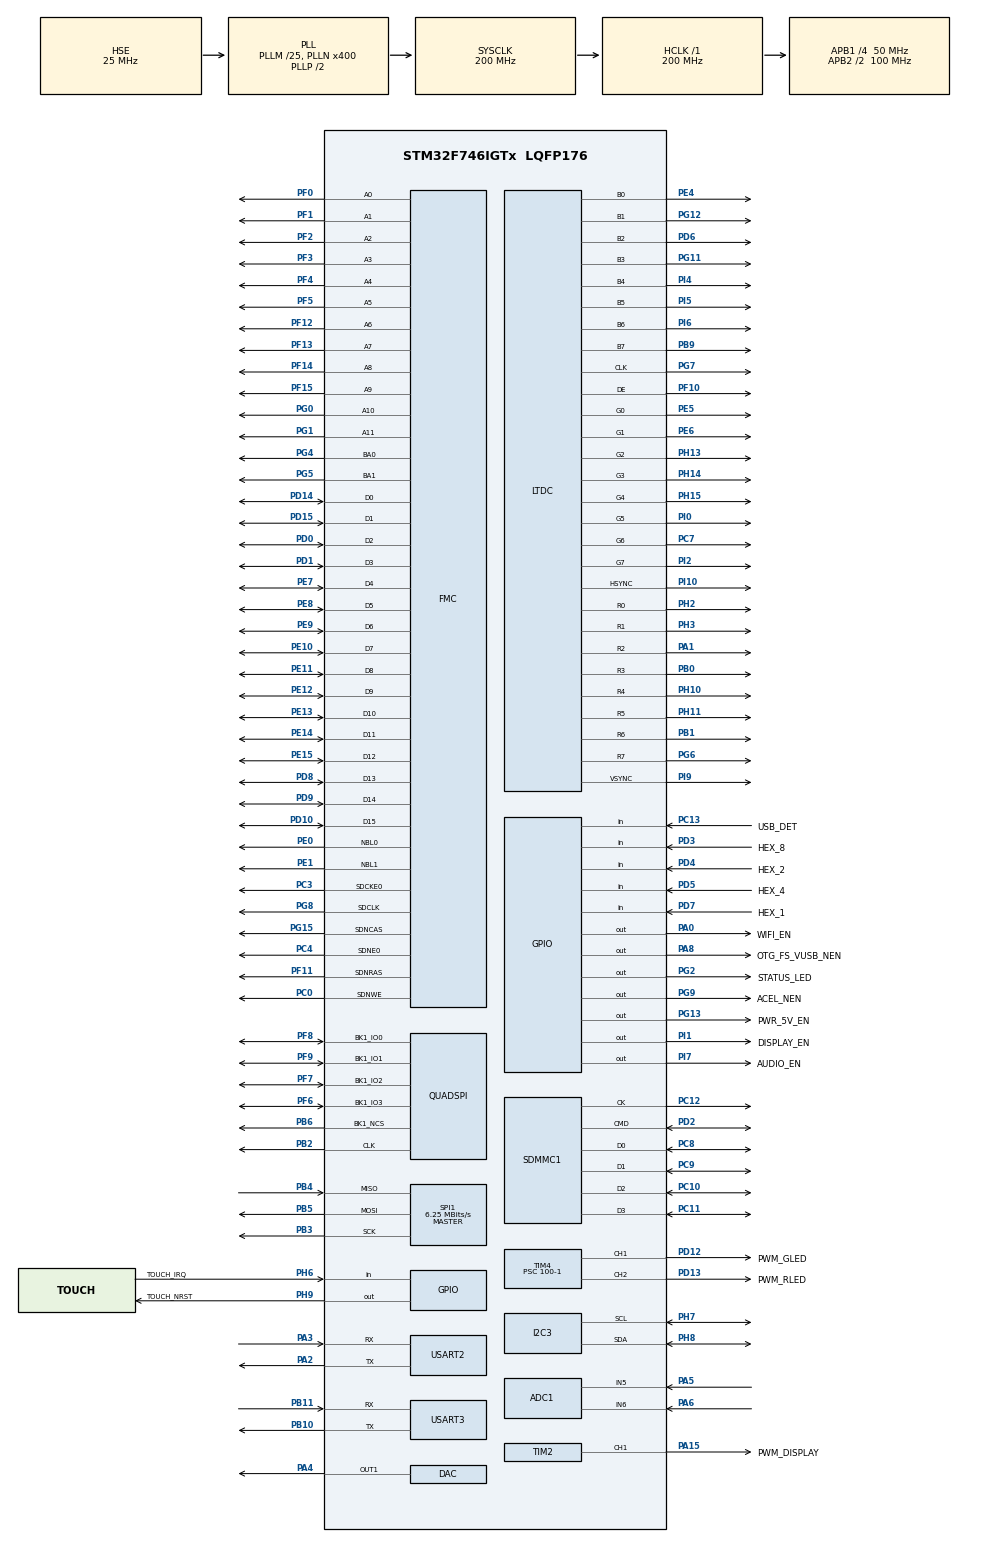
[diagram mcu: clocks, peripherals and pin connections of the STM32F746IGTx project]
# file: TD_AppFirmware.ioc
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FREERTOS.Queues01=AudioQueue,5,Type_AudioMsg,0,Dynamic,NULL,NULL
PD12.GPIO_Label=PWM_GLED
FATFS._USE_LFN=2
FMC.SDClockPeriod1=FMC_SDRAM_CLOCK_PERIOD_2
SH.FMC_A0.0=FMC_A0,12b-sda1
FATFS0.BSP.api=Unknown
VP_ADC1_TempSens_Input.Mode=IN-TempSens
NVIC.TIM6_DAC_IRQn=true\:0\:0\:false\:false\:true\:false\:false\:true
PG8.Signal=FMC_SDCLK
PG0.Signal=FMC_A10
SH.FMC_D5_DA5.0=FMC_D5,sd-16b-d1
VP_TIM1_VS_no_output1.Mode=Output Compare1 No Output
SH.FMC_D9_DA9.0=FMC_D9,sd-16b-d1
PF7.Signal=QUADSPI_BK1_IO2
NVIC.DMA2D_IRQn=true\:5\:0\:false\:false\:true\:true\:true\:true
RCC.PLL48CLockSelection=RCC_CLK48SOURCE_PLLSAIP
SH.FMC_SDNWE.0=FMC_SDNWE,12b-sda1
PH9.Signal=GPIO_Output
SPI1.Direction=SPI_DIRECTION_2LINES
SH.FMC_D11_DA11.0=FMC_D11,sd-16b-d1
Dma.SDMMC1_TX.2.Direction=DMA_MEMORY_TO_PERIPH
RCC.APB2TimFreq_Value=200000000
PB6.Signal=QUADSPI_BK1_NCS
Dma.ADC1.0.Direction=DMA_PERIPH_TO_MEMORY
PC7.Signal=LTDC_G6
SPI1.CalculateBaudRate=6.25 MBits/s
PD0.Signal=FMC_D2_DA2
PD8.Signal=FMC_D13_DA13
PE1.Signal=FMC_NBL1
QUADSPI.FlashSize=24
Dma.ADC1.0.MemDataAlignment=DMA_MDATAALIGN_HALFWORD
FATFS0.BSP.ip=GPIO
PB3.Mode=Full_Duplex_Master
ADC1.ScanConvMode=ADC_SCAN_ENABLE
FMC.SelfRefreshTime1=4
LTDC.PixelFormat_L0=LTDC_PIXEL_FORMAT_RGB888
PE9.Signal=FMC_D6_DA6
SH.FMC_A2.0=FMC_A2,12b-sda1
Dma.SDMMC1_TX.2.FIFOMode=DMA_FIFOMODE_ENABLE
SPI1.DataSize=SPI_DATASIZE_8BIT
PC9.Mode=SD_4_bits_Wide_bus
PA8.Signal=GPIO_Output
SH.FMC_D1_DA1.0=FMC_D1,sd-16b-d1
LTDC.HSync=41
PB9.Signal=LTDC_B7
Mcu.Package=LQFP176
TIM2.Prescaler=100-1
PB1.Signal=LTDC_R6
NVIC.TimeBase=TIM6_DAC_IRQn
PD12.Signal=S_TIM4_CH1
PH11.Mode=RGB888
NVIC.TimeBaseIP=TIM6
FMC.WriteRecoveryTime1=3
PC11.Mode=SD_4_bits_Wide_bus
RCC.APB2CLKDivider=RCC_HCLK_DIV2
SH.S_TIM4_CH1.0=TIM4_CH1,PWM Generation1 CH1
LTDC.VSync=10
RCC.APB1TimFreq_Value=100000000
PF10.Mode=RGB888
FMC.RowCycleDelay1=7
Dma.SDMMC1_TX.2.Instance=DMA2_Stream6
PH8.Mode=I2C
ADC1.EOCSelection=ADC_EOC_SEQ_CONV
PD15.Signal=FMC_D1_DA1
PG12.Signal=LTDC_B1
FATFS0.BSP.STBoard=false
SH.FMC_A4.0=FMC_A4,12b-sda1
FREERTOS.Tasks01=DefaultTouchGFx,24,8192,defaultTouchGFxTask,Default,NULL,Dynamic,NULL,NULL;GeneralHardware,8,512,generalHardwareTask,Default,NULL,Dynamic,NULL,NULL;AnalogDigital,8,128,analogDigitalTask,Default,NULL,Dynamic,NULL,NULL;PWM_Acceleromet,8,1024,PWM_AccelerometerTask,Default,NULL,Dynamic,NULL,NULL;WIFI_AP,8,256,WIFI_AP_Task,Default,NULL,Dynamic,NULL,NULL;AudioPlay,8,4096,audioPlayTask,Default,NULL,Dynamic,NULL,NULL
PH13.Signal=LTDC_G2
Dma.SDMMC1_RX.1.MemInc=DMA_MINC_ENABLE
TIM3.AutoReloadPreload=TIM_AUTORELOAD_PRELOAD_DISABLE
SH.ADCx_IN6.0=ADC1_IN6,IN6
PG5.Signal=FMC_A15_BA1
PC13.Signal=GPIO_Input
SH.FMC_D10_DA10.0=FMC_D10,sd-16b-d1
FATFS0.BSP.mode=Input
PD3.Signal=GPIO_Input
PI10.Mode=RGB888
PD6.Mode=RGB888
RCC.PLLSAIRDiv=RCC_PLLSAIDIVR_8
LTDC.ImageWidth_L0=480
PD10.Signal=FMC_D15_DA15
PA3.Mode=Asynchronous
TIM1.AutoReloadPreload=TIM_AUTORELOAD_PRELOAD_ENABLE
PA8.GPIO_Label=OTG_FS_VUSB_NEN
Dma.ADC1.0.Priority=DMA_PRIORITY_LOW
PI6.Mode=RGB888
NVIC.DMA2_Stream6_IRQn=true\:15\:0\:true\:false\:true\:true\:false\:true
PA5.Signal=ADCx_IN5
PC12.Mode=SD_4_bits_Wide_bus
NVIC.TIM3_IRQn=true\:5\:0\:false\:false\:true\:true\:true\:true
PI7.Signal=GPIO_Output
FMC.ReadBurst1=FMC_SDRAM_RBURST_ENABLE
TIM1.TIM_MasterOutputTrigger=TIM_TRGO_UPDATE
SH.FMC_A6.0=FMC_A6,12b-sda1
PE14.Signal=FMC_D11_DA11
PE6.Mode=RGB888
SPI1.Mode=SPI_MODE_MASTER
PI2.Signal=LTDC_G7
QUADSPI.FifoThreshold=4
PF13.Signal=FMC_A7
TIM2.Period=100-1
Dma.SDMMC1_TX.2.MemInc=DMA_MINC_ENABLE
ADC1.ExternalTrigConv=ADC_EXTERNALTRIGCONV_T1_TRGO
PC8.Mode=SD_4_bits_Wide_bus
ADC1.master=1
Dma.SDMMC1_RX.1.MemBurst=DMA_MBURST_INC4
ProjectManager.HeapSize=0xA00
PB1.Mode=RGB888
PH6.Signal=GPIO_Input
NVIC.PriorityGroup=NVIC_PRIORITYGROUP_4
Dma.SDMMC1_RX.1.Priority=DMA_PRIORITY_LOW
PC15/OSC32_OUT.Signal=RCC_OSC32_OUT
PF4.Signal=FMC_A4
PD2.Signal=SDMMC1_CMD
FATFS0.BSP.name=Detect_SDIO
PI1.GPIO_Label=DISPLAY_EN
Mcu.Family=STM32F7
SH.FMC_A8.0=FMC_A8,12b-sda1
FREERTOS.BinarySemaphores01=BinarySemAnalogDigital,Dynamic,NULL;BinarySemPWM_Accelerometer,Dynamic,NULL;BinarySemWIFI_AP,Dynamic,NULL
PH14.Signal=LTDC_G3
PH10.Signal=LTDC_R4
SH.FMC_D14_DA14.0=FMC_D14,sd-16b-d1
PG2.Signal=GPIO_Output
PC14/OSC32_IN.Mode=LSE-External-Oscillator
SH.FMC_A14_BA0.0=FMC_BA0,FourSdramBanks1
SH.FMC_A11.0=FMC_A11,12b-sda1
PI5.Mode=RGB888
PG11.Signal=LTDC_B3
PG15.Signal=FMC_SDNCAS
PD13.Signal=S_TIM4_CH2
PA15.GPIO_Label=PWM_DISPLAY
TIM1.Prescaler=1000-1
STMicroelectronics.X-CUBE-TOUCHGFX.4.16.0.tgfx_location=By Address
ADC1.Channel-3\#ChannelRegularConversion=ADC_CHANNEL_TEMPSENSOR
TIM3.Period=1000-1
Dma.SDMMC1_TX.2.FIFOThreshold=DMA_FIFO_THRESHOLD_FULL
PH10.Mode=RGB888
SH.FMC_NBL1.0=FMC_NBL1,Sd2ByteEnable1
LTDC.WindowX1_L0=480
PI9.Mode=RGB888
ADC1.Channel-0\#ChannelRegularConversion=ADC_CHANNEL_5
RCC.HSE_VALUE=25000000
STMicroelectronics.X-CUBE-TOUCHGFX.4.16.0.tgfx_display_interface=disp_ltdc
FMC.ExitSelfRefreshDelay1=7
PF9.Mode=Single Bank 1
PA14.Mode=Serial_Wire
TIM3.Prescaler=100-1
PF11.Signal=FMC_SDNRAS
PB5.Mode=Full_Duplex_Master
TIM2.Channel-PWM\ Generation1\ CH1=TIM_CHANNEL_1
QUADSPI.SampleShifting=QSPI_SAMPLE_SHIFTING_HALFCYCLE
PD13.GPIO_Label=PWM_RLED
PA6.Signal=ADCx_IN6
PD5.GPIO_Label=HEX_4
PA15.Signal=S_TIM2_CH1_ETR
PF8.Signal=QUADSPI_BK1_IO0
I2C3.Timing=0x00C0EAFF
Dma.Request2=SDMMC1_TX
Dma.Request1=SDMMC1_RX
PD3.GPIO_Label=HEX_8
PH2.Mode=RGB888
PE7.Signal=FMC_D4_DA4
Dma.SDMMC1_RX.1.PeriphInc=DMA_PINC_DISABLE
PD6.Signal=LTDC_B2
Dma.Request0=ADC1
VP_TIM3_VS_ClockSourceINT.Mode=Internal
PB4.Signal=SPI1_MISO
PG2.GPIO_Label=STATUS_LED
PA3.Signal=USART2_RX
QUADSPI.ChipSelectHighTime=QSPI_CS_HIGH_TIME_6_CYCLE
NVIC.LTDC_IRQn=true\:5\:0\:false\:false\:true\:true\:true\:true
LTDC.WindowY1_L0=272
PG7.Signal=LTDC_CLK
PC11.Signal=SDMMC1_D3
PC8.Signal=SDMMC1_D0
PC10.Mode=SD_4_bits_Wide_bus
PD9.Signal=FMC_D14_DA14
FATFS0.BSP.instance=PC13
PA13.Signal=SYS_JTMS-SWDIO
Dma.ADC1.0.PeriphDataAlignment=DMA_PDATAALIGN_HALFWORD
PF6.Signal=QUADSPI_BK1_IO3
SH.FMC_D13_DA13.0=FMC_D13,sd-16b-d1
PH8.Signal=I2C3_SDA
Dma.SDMMC1_RX.1.MemDataAlignment=DMA_MDATAALIGN_WORD
PB9.Mode=RGB888
RCC.USBFreq_Value=48000000
PH13.Mode=RGB888
TIM4.Prescaler=100-1
PA1.Signal=LTDC_R2
PD2.Mode=SD_4_bits_Wide_bus
board=custom
PG12.Mode=RGB888
RCC.VCOOutputFreq_Value=400000000
PI9.Signal=LTDC_VSYNC
PI4.Signal=LTDC_B4
PE5.Mode=RGB888
SH.FMC_D12_DA12.0=FMC_D12,sd-16b-d1
PF1.Signal=FMC_A1
ADC1.NbrOfConversion=3
PE0.Signal=FMC_NBL0
PE12.Signal=FMC_D9_DA9
RCC.SYSCLKFreq_VALUE=200000000
ADC1.Rank-3\#ChannelRegularConversion=3
ADC1.SamplingTime-3\#ChannelRegularConversion=ADC_SAMPLETIME_480CYCLES
PB2.Mode=Single Bank 1
Dma.ADC1.0.MemInc=DMA_MINC_ENABLE
RCC.HSI_VALUE=16000000
RCC.PLLQ=8
PH3.Signal=LTDC_R1
RCC.PLLM=25
RCC.PLLN=400
PA2.Mode=Asynchronous
Dma.SDMMC1_RX.1.FIFOThreshold=DMA_FIFO_THRESHOLD_FULL
CORTEX_M7.CPU_DCache=Enabled
PH9.PinState=GPIO_PIN_SET
VP_CRC_VS_CRC.Mode=CRC_Activate
LTDC.ImageHeight_L0=272
SH.FMC_D7_DA7.0=FMC_D7,sd-16b-d1
VP_SYS_VS_tim6.Mode=TIM6
FMC.RCDDelay1=2
Dma.SDMMC1_RX.1.PeriphDataAlignment=DMA_PDATAALIGN_WORD
QUADSPI.ClockPrescaler=1
SPI1.VirtualType=VM_MASTER
PB10.Mode=Asynchronous
VP_FATFS_VS_SDIO.Mode=SDIO
PG4.Signal=FMC_A14_BA0
PC12.Signal=SDMMC1_CK
PH6.GPIO_Label=TOUCH_IRQ
FMC.LoadToActiveDelay1=2
VP_STMicroelectronics.X-CUBE-TOUCHGFX_VS_GraphicsJjApplication_4.16.0.Mode=GraphicsJjApplication
PG6.Mode=RGB888
PG13.Signal=GPIO_Output
RCC.SYSCLKSource=RCC_SYSCLKSOURCE_PLLCLK
SH.FMC_A15_BA1.0=FMC_BA1,FourSdramBanks1
USART3.VirtualMode-Asynchronous=VM_ASYNC
NVIC.SDMMC1_IRQn=true\:14\:0\:true\:false\:true\:true\:true\:true
STMicroelectronics.X-CUBE-TOUCHGFX.4.16.0.tgfx_hardware_accelerator=dma_2d
Dma.SDMMC1_TX.2.PeriphInc=DMA_PINC_DISABLE
PD4.Signal=GPIO_Input
TIM4.Pulse-PWM\ Generation1\ CH1=50-1
PH1/OSC_OUT.Signal=RCC_OSC_OUT
PB6.Mode=Single Bank 1
PC3.Signal=FMC_SDCKE0
PE5.Signal=LTDC_G0
PB2.Signal=QUADSPI_CLK
FATFS0.BSP.i2caddr=0
PI6.Signal=LTDC_B6
Dma.ADC1.0.PeriphInc=DMA_PINC_DISABLE
SH.S_TIM4_CH2.0=TIM4_CH2,PWM Generation2 CH2
PF8.Mode=Single Bank 1
TIM4.Period=100-1
PF3.Signal=FMC_A3
PE10.Signal=FMC_D7_DA7
ADC1.SamplingTime-0\#ChannelRegularConversion=ADC_SAMPLETIME_28CYCLES
RCC.SDMMCClockSelection=RCC_SDMMC1CLKSOURCE_CLK48
FATFS0.BSP.solution=PC13
SH.FMC_A1.0=FMC_A1,12b-sda1
PH2.Signal=LTDC_R0
SH.FMC_SDCLK.0=FMC_SDCLK,12b-sda1
PF14.Signal=FMC_A8
VP_DMA2D_VS_DMA2D.Mode=DMA2D_Activate
Dma.ADC1.0.FIFOMode=DMA_FIFOMODE_DISABLE
TIM1.Period=100-1
SH.FMC_D3_DA3.0=FMC_D3,sd-16b-d1
TIM4.Pulse-PWM\ Generation2\ CH2=50-1
PC4.Mode=SdramChipSelect1_1
PH15.Signal=LTDC_G4
Dma.ADC1.0.Instance=DMA2_Stream0
ADC1.Rank-0\#ChannelRegularConversion=1
PI4.Mode=RGB888
PG9.Signal=GPIO_Output
TIM1.Channel-Output\ Compare1\ No\ Output=TIM_CHANNEL_1
PD7.Signal=GPIO_Input
PD1.Signal=FMC_D3_DA3
STMicroelectronics.X-CUBE-TOUCHGFX.4.16.0.tgfx_buffering_strategy=Double
PC0.Signal=FMC_SDNWE
Dma.SDMMC1_TX.2.PeriphBurst=DMA_PBURST_INC4
RCC.APB1CLKDivider=RCC_HCLK_DIV4
Dma.SDMMC1_TX.2.MemBurst=DMA_MBURST_INC4
PG13.GPIO_Label=PWR_5V_EN
PI2.Mode=RGB888
SH.FMC_A3.0=FMC_A3,12b-sda1
FMC.CASLatency1=FMC_SDRAM_CAS_LATENCY_3
PB11.Mode=Asynchronous
SH.FMC_D15_DA15.0=FMC_D15,sd-16b-d1
PB10.Signal=USART3_TX
FATFS.BSP.number=1
PH9.GPIO_Label=TOUCH_NRST
PH14.Mode=RGB888
Dma.SDMMC1_TX.2.Priority=DMA_PRIORITY_LOW
PA1.Mode=RGB888
PE15.Signal=FMC_D12_DA12
PE8.Signal=FMC_D5_DA5
PI1.Signal=GPIO_Output
PA0/WKUP.GPIO_Label=WIFI_EN
ADC1.DMAContinuousRequests=ENABLE
PA13.Mode=Serial_Wire
SH.FMC_SDNCAS.0=FMC_SDNCAS,12b-sda1
Dma.SDMMC1_TX.2.Mode=DMA_PFCTRL
PA4.Signal=COMP_DAC1_group
ADC1.SamplingTime-1\#ChannelRegularConversion=ADC_SAMPLETIME_15CYCLES
PB5.Signal=SPI1_MOSI
ADC1.Rank-1\#ChannelRegularConversion=2
SH.FMC_A5.0=FMC_A5,12b-sda1
PG11.Mode=RGB888
LTDC.Alpha_L0=255
Dma.SDMMC1_RX.1.PeriphBurst=DMA_PBURST_INC4
SH.S_TIM2_CH1_ETR.0=TIM2_CH1,PWM Generation1 CH1
PF6.Mode=Single Bank 1
NVIC.TIM1_UP_TIM10_IRQn=true\:5\:0\:false\:false\:true\:true\:true\:true
PF9.Signal=QUADSPI_BK1_IO1
STMicroelectronics.X-CUBE-TOUCHGFX.4.16.0.tgfx_vsync=vsync_ltdc
SH.ADCx_IN5.0=ADC1_IN5,IN5
VP_TIM4_VS_ClockSourceINT.Mode=Internal
PB0.Signal=LTDC_R3
Dma.SDMMC1_RX.1.Direction=DMA_PERIPH_TO_MEMORY
NVIC.USART3_IRQn=true\:5\:0\:false\:false\:true\:true\:true\:true
PC3.Mode=SdramChipSelect1_1
RCC.CortexFreq_Value=200000000
PG6.Signal=LTDC_R7
USART2.SwapParam=ADVFEATURE_SWAP_ENABLE
LTDC.HBP=13
PC10.Signal=SDMMC1_D2
SH.FMC_NBL0.0=FMC_NBL0,Sd2ByteEnable1
SH.FMC_D6_DA6.0=FMC_D6,sd-16b-d1
PA0/WKUP.Signal=GPIO_Output
PC13.GPIO_Label=USB_DET
PB11.Signal=USART3_RX
ProjectManager.StackSize=0xA00
VP_FREERTOS_VS_CMSIS_V2.Mode=CMSIS_V2
PH3.Mode=RGB888
Dma.SDMMC1_TX.2.MemDataAlignment=DMA_MDATAALIGN_WORD
SH.FMC_A7.0=FMC_A7,12b-sda1
Dma.SDMMC1_RX.1.Mode=DMA_PFCTRL
PH0/OSC_IN.Mode=HSE-External-Oscillator
RCC.HCLKFreq_Value=200000000
STMicroelectronics.X-CUBE-TOUCHGFX.4.16.0.tgfx_oswrapper=CMSIS V2
PF12.Signal=FMC_A6
NVIC.DMA2_Stream0_IRQn=true\:7\:0\:true\:false\:true\:true\:false\:true
SH.FMC_A10.0=FMC_A10,12b-sda1
RCC.AHBFreq_Value=200000000
SH.FMC_D8_DA8.0=FMC_D8,sd-16b-d1
USART2.VirtualMode-Asynchronous=VM_ASYNC
FMC.RPDelay1=2
SH.FMC_D2_DA2.0=FMC_D2,sd-16b-d1
PB4.Mode=Full_Duplex_Master
PE13.Signal=FMC_D10_DA10
PI5.Signal=LTDC_B5
PI0.Signal=LTDC_G5
LTDC.HFP=32
PE4.Mode=RGB888
SH.FMC_SDNRAS.0=FMC_SDNRAS,12b-sda1
DMA2D.ColorMode=DMA2D_OUTPUT_RGB888
LTDC.ActiveW=480
PE4.Signal=LTDC_B0
PH1/OSC_OUT.Mode=HSE-External-Oscillator
FREERTOS.configTOTAL_HEAP_SIZE=60000
STMicroelectronics.X-CUBE-TOUCHGFX.4.16.0.tgfx_address1=0xC0000000
STMicroelectronics.X-CUBE-TOUCHGFX.4.16.0.tgfx_address2=0xC005FA00
PH7.Mode=I2C
PD7.GPIO_Label=HEX_1
SH.FMC_D0_DA0.0=FMC_D0,sd-16b-d1
PC14/OSC32_IN.Signal=RCC_OSC32_IN
SH.FMC_A9.0=FMC_A9,12b-sda1
SH.FMC_D4_DA4.0=FMC_D4,sd-16b-d1
RCC.PLLSAIN=384
PF5.Signal=FMC_A5
RCC.PLLSAIP=RCC_PLLSAIP_DIV8
RCC.PLLSAIR=5
PH7.Signal=I2C3_SCL
PF0.Signal=FMC_A0
SPI1.BaudRatePrescaler=SPI_BAUDRATEPRESCALER_16
RCC.PLLSourceVirtual=RCC_PLLSOURCE_HSE
TIM4.Channel-PWM\ Generation1\ CH1=TIM_CHANNEL_1
SH.COMP_DAC1_group.0=DAC_OUT1,DAC_OUT1
LTDC.FBStartAdress_L0=0xC0000000
CORTEX_M7.CPU_ICache=Enabled
PH11.Signal=LTDC_R5
Dma.SDMMC1_RX.1.Instance=DMA2_Stream3
PG1.Signal=FMC_A11
PC4.Signal=FMC_SDNE0
PI10.Signal=LTDC_HSYNC
PD5.Signal=GPIO_Input
NVIC.USART2_IRQn=true\:5\:0\:false\:false\:true\:true\:true\:true
TIM2.Pulse-PWM\ Generation1\ CH1=50-1
PF7.Mode=Single Bank 1
ProjectManager.TargetToolchain=STM32CubeIDE
Dma.ADC1.0.Mode=DMA_CIRCULAR
LTDC.ActiveH=272
PI0.Mode=RGB888
ADC1.Channel-1\#ChannelRegularConversion=ADC_CHANNEL_6
PF2.Signal=FMC_A2
STMicroelectronics.X-CUBE-TOUCHGFX.4.16.0.ApplicationCcGraphicsJjApplication=TouchGFXOoGenerator
NVIC.DMA2_Stream3_IRQn=true\:15\:0\:true\:false\:true\:true\:false\:true
PE11.Signal=FMC_D8_DA8
PG7.Mode=RGB888
PG9.GPIO_Label=ACEL_NEN
PB0.Mode=RGB888
PH0/OSC_IN.Signal=RCC_OSC_IN
TIM4.Channel-PWM\ Generation2\ CH2=TIM_CHANNEL_2
RCC.APB2Freq_Value=100000000
LTDC.Layers=0
VP_TIM2_VS_ClockSourceINT.Mode=Internal
PD4.GPIO_Label=HEX_2
PF10.Signal=LTDC_DE
PI7.GPIO_Label=AUDIO_EN
PF15.Signal=FMC_A9
PE6.Signal=LTDC_G1
Dma.SDMMC1_RX.1.FIFOMode=DMA_FIFOMODE_ENABLE
Mcu.Name=STM32F746IGTx
PA2.Signal=USART2_TX
Dma.SDMMC1_TX.2.PeriphDataAlignment=DMA_PDATAALIGN_WORD
PH15.Mode=RGB888
PD14.Signal=FMC_D0_DA0
PB3.Signal=SPI1_SCK
PC15/OSC32_OUT.Mode=LSE-External-Oscillator
PA14.Signal=SYS_JTCK-SWCLK
ADC1.NbrOfConversionFlag=1
PC9.Signal=SDMMC1_D1
PC7.Mode=RGB888
RCC.APB1Freq_Value=50000000

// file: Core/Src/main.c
/* USER CODE BEGIN Header */
/**
  ******************************************************************************
  * @file           : main.c
  * @brief          : Main program body
  ******************************************************************************
  * @attention
  *
  * <h2><center>&copy; Copyright (c) 2021 STMicroelectronics.
  * All rights reserved.</center></h2>
  *
  * This software component is licensed by ST under BSD 3-Clause license,
  * the "License"; You may not use this file except in compliance with the
  * License. You may obtain a copy of the License at:
  *                        opensource.org/licenses/BSD-3-Clause
  *
  ******************************************************************************
  */
/* USER CODE END Header */
#include "main.h"
#include "cmsis_os.h"
#include "adc.h"
#include "crc.h"
#include "dac.h"
#include "dma.h"
#include "dma2d.h"
#include "fatfs.h"
#include "i2c.h"
#include "ltdc.h"
#include "quadspi.h"
#include "sdmmc.h"
#include "spi.h"
#include "tim.h"
#include "usart.h"
#include "gpio.h"
#include "fmc.h"
#include "app_touchgfx.h"

/* USER CODE BEGIN Includes */
#include "MainSupport.h"
#include "AudioPlayTaskSupport.h"
/* USER CODE END Includes */

void SystemClock_Config(void);
void MX_FREERTOS_Init(void);

int main(void)
{

  /* Enable I-Cache---------------------------------------------------------*/
  SCB_EnableICache();

  /* Enable D-Cache---------------------------------------------------------*/
  SCB_EnableDCache();

  /* MCU Configuration--------------------------------------------------------*/

  /* Reset of all peripherals, Initializes the Flash interface and the Systick. */
  HAL_Init();

  /* Configure the system clock */
  SystemClock_Config();

  /* Initialize all configured peripherals */
  MX_GPIO_Init();
  MX_DMA_Init();
  MX_DMA2D_Init();
  MX_FMC_Init();
  MX_LTDC_Init();
  MX_QUADSPI_Init();
  MX_CRC_Init();
  MX_I2C3_Init();
  MX_TIM2_Init();
  MX_USART3_UART_Init();
  MX_ADC1_Init();
  MX_TIM1_Init();
  MX_SPI1_Init();
  MX_TIM4_Init();
  MX_USART2_UART_Init();
  MX_DAC_Init();
  MX_SDMMC1_SD_Init();
  MX_TIM3_Init();
  MX_FATFS_Init();
  MX_TouchGFX_Init();

  /* Init scheduler */
  osKernelInitialize();  /* Call init function for freertos objects (in freertos.c) */
  MX_FREERTOS_Init();
  /* Start scheduler */
  osKernelStart();

  /* We should never get here as control is now taken by the scheduler */
  /* Infinite loop */
  while (1)
  {

  }
}

void SystemClock_Config(void)
{
  RCC_OscInitTypeDef RCC_OscInitStruct = {0};
  RCC_ClkInitTypeDef RCC_ClkInitStruct = {0};
  RCC_PeriphCLKInitTypeDef PeriphClkInitStruct = {0};

  /** Configure LSE Drive Capability
  */
  HAL_PWR_EnableBkUpAccess();
  /** Configure the main internal regulator output voltage
  */
  __HAL_RCC_PWR_CLK_ENABLE();
  __HAL_PWR_VOLTAGESCALING_CONFIG(PWR_REGULATOR_VOLTAGE_SCALE1);
  /** Initializes the RCC Oscillators according to the specified parameters
  * in the RCC_OscInitTypeDef structure.
  */
  RCC_OscInitStruct.OscillatorType = RCC_OSCILLATORTYPE_HSE;
  RCC_OscInitStruct.HSEState = RCC_HSE_ON;
  RCC_OscInitStruct.PLL.PLLState = RCC_PLL_ON;
  RCC_OscInitStruct.PLL.PLLSource = RCC_PLLSOURCE_HSE;
  RCC_OscInitStruct.PLL.PLLM = 25;
  RCC_OscInitStruct.PLL.PLLN = 400;
  RCC_OscInitStruct.PLL.PLLP = RCC_PLLP_DIV2;
  RCC_OscInitStruct.PLL.PLLQ = 8;
  if (HAL_RCC_OscConfig(&RCC_OscInitStruct) != HAL_OK)
  {
    Error_Handler();
  }
  /** Activate the Over-Drive mode
  */
  if (HAL_PWREx_EnableOverDrive() != HAL_OK)
  {
    Error_Handler();
  }
  /** Initializes the CPU, AHB and APB buses clocks
  */
  RCC_ClkInitStruct.ClockType = RCC_CLOCKTYPE_HCLK|RCC_CLOCKTYPE_SYSCLK
                              |RCC_CLOCKTYPE_PCLK1|RCC_CLOCKTYPE_PCLK2;
  RCC_ClkInitStruct.SYSCLKSource = RCC_SYSCLKSOURCE_PLLCLK;
  RCC_ClkInitStruct.AHBCLKDivider = RCC_SYSCLK_DIV1;
  RCC_ClkInitStruct.APB1CLKDivider = RCC_HCLK_DIV4;
  RCC_ClkInitStruct.APB2CLKDivider = RCC_HCLK_DIV2;

  if (HAL_RCC_ClockConfig(&RCC_ClkInitStruct, FLASH_LATENCY_6) != HAL_OK)
  {
    Error_Handler();
  }
  PeriphClkInitStruct.PeriphClockSelection = RCC_PERIPHCLK_LTDC|RCC_PERIPHCLK_USART2
                              |RCC_PERIPHCLK_USART3|RCC_PERIPHCLK_I2C3
                              |RCC_PERIPHCLK_SDMMC1|RCC_PERIPHCLK_CLK48;
  PeriphClkInitStruct.PLLSAI.PLLSAIN = 384;
  PeriphClkInitStruct.PLLSAI.PLLSAIR = 5;
  PeriphClkInitStruct.PLLSAI.PLLSAIQ = 2;
  PeriphClkInitStruct.PLLSAI.PLLSAIP = RCC_PLLSAIP_DIV8;
  PeriphClkInitStruct.PLLSAIDivQ = 1;
  PeriphClkInitStruct.PLLSAIDivR = RCC_PLLSAIDIVR_8;
  PeriphClkInitStruct.Usart2ClockSelection = RCC_USART2CLKSOURCE_PCLK1;
  PeriphClkInitStruct.Usart3ClockSelection = RCC_USART3CLKSOURCE_PCLK1;
  PeriphClkInitStruct.I2c3ClockSelection = RCC_I2C3CLKSOURCE_PCLK1;
  PeriphClkInitStruct.Clk48ClockSelection = RCC_CLK48SOURCE_PLLSAIP;
  PeriphClkInitStruct.Sdmmc1ClockSelection = RCC_SDMMC1CLKSOURCE_CLK48;
  if (HAL_RCCEx_PeriphCLKConfig(&PeriphClkInitStruct) != HAL_OK)
  {
    Error_Handler();
  }
}

 /**
  * @brief  Period elapsed callback in non blocking mode
  * @note   This function is called  when TIM6 interrupt took place, inside
  * HAL_TIM_IRQHandler(). It makes a direct call to HAL_IncTick() to increment
  * a global variable "uwTick" used as application time base.
  * @param  htim : TIM handle
  * @retval None
  */
void HAL_TIM_PeriodElapsedCallback(TIM_HandleTypeDef *htim)
{
  if (htim->Instance == TIM6) {
    HAL_IncTick();
  }
  /* USER CODE BEGIN Callback 1 */
  if (htim->Instance == TIM3)
	  callbackHandlerTimer3();

  /* USER CODE END Callback 1 */
}

void Error_Handler(void)
{
  __disable_irq();
  while (1)
  {
  }
}

/************************ (C) COPYRIGHT STMicroelectronics *****END OF FILE****/

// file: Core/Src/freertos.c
/* USER CODE BEGIN Header */
/**
  ******************************************************************************
  * File Name          : freertos.c
  * Description        : Code for freertos applications
  ******************************************************************************
  * @attention
  *
  * <h2><center>&copy; Copyright (c) 2021 STMicroelectronics.
  * All rights reserved.</center></h2>
  *
  * This software component is licensed by ST under Ultimate Liberty license
  * SLA0044, the "License"; You may not use this file except in compliance with
  * the License. You may obtain a copy of the License at:
  *                             www.st.com/SLA0044
  *
  ******************************************************************************
  */
/* USER CODE END Header */

#include "FreeRTOS.h"
#include "task.h"
#include "main.h"
#include "cmsis_os.h"

/* USER CODE BEGIN Includes */
#include "MainSupport.h"
#include "TD_SDRAM.h"
#include "TD_SupportIO.h"
#include "app_touchgfx.h"
#include "AnalogDigitalTaskSupport.h"
#include "PWM_AccelerometerTaskSupport.h"
#include "AudioPlayTaskSupport.h"
/* USER CODE END Includes */

/* Definitions for DefaultTouchGFx */
osThreadId_t DefaultTouchGFxHandle;
const osThreadAttr_t DefaultTouchGFx_attributes = {
  .name = "DefaultTouchGFx",
  .priority = (osPriority_t) osPriorityNormal,
  .stack_size = 8192 * 4
};
/* Definitions for GeneralHardware */
osThreadId_t GeneralHardwareHandle;
const osThreadAttr_t GeneralHardware_attributes = {
  .name = "GeneralHardware",
  .priority = (osPriority_t) osPriorityLow,
  .stack_size = 512 * 4
};
/* Definitions for AnalogDigital */
osThreadId_t AnalogDigitalHandle;
const osThreadAttr_t AnalogDigital_attributes = {
  .name = "AnalogDigital",
  .priority = (osPriority_t) osPriorityLow,
  .stack_size = 128 * 4
};
/* Definitions for PWM_Acceleromet */
osThreadId_t PWM_AccelerometHandle;
const osThreadAttr_t PWM_Acceleromet_attributes = {
  .name = "PWM_Acceleromet",
  .priority = (osPriority_t) osPriorityLow,
  .stack_size = 1024 * 4
};
/* Definitions for WIFI_AP */
osThreadId_t WIFI_APHandle;
const osThreadAttr_t WIFI_AP_attributes = {
  .name = "WIFI_AP",
  .priority = (osPriority_t) osPriorityLow,
  .stack_size = 256 * 4
};
/* Definitions for AudioPlay */
osThreadId_t AudioPlayHandle;
const osThreadAttr_t AudioPlay_attributes = {
  .name = "AudioPlay",
  .priority = (osPriority_t) osPriorityLow,
  .stack_size = 4096 * 4
};
/* Definitions for AudioQueue */
osMessageQueueId_t AudioQueueHandle;
const osMessageQueueAttr_t AudioQueue_attributes = {
  .name = "AudioQueue"
};
/* Definitions for BinarySemAnalogDigital */
osSemaphoreId_t BinarySemAnalogDigitalHandle;
const osSemaphoreAttr_t BinarySemAnalogDigital_attributes = {
  .name = "BinarySemAnalogDigital"
};
/* Definitions for BinarySemPWM_Accelerometer */
osSemaphoreId_t BinarySemPWM_AccelerometerHandle;
const osSemaphoreAttr_t BinarySemPWM_Accelerometer_attributes = {
  .name = "BinarySemPWM_Accelerometer"
};
/* Definitions for BinarySemWIFI_AP */
osSemaphoreId_t BinarySemWIFI_APHandle;
const osSemaphoreAttr_t BinarySemWIFI_AP_attributes = {
  .name = "BinarySemWIFI_AP"
};

void defaultTouchGFxTask(void *argument);
void generalHardwareTask(void *argument);
void analogDigitalTask(void *argument);
void PWM_AccelerometerTask(void *argument);
void WIFI_AP_Task(void *argument);
void audioPlayTask(void *argument);

void MX_FREERTOS_Init(void); /* (MISRA C 2004 rule 8.1) */

void MX_FREERTOS_Init(void) {

  /* Create the semaphores(s) */
  /* creation of BinarySemAnalogDigital */
  BinarySemAnalogDigitalHandle = osSemaphoreNew(1, 1, &BinarySemAnalogDigital_attributes);

  /* creation of BinarySemPWM_Accelerometer */
  BinarySemPWM_AccelerometerHandle = osSemaphoreNew(1, 1, &BinarySemPWM_Accelerometer_attributes);

  /* creation of BinarySemWIFI_AP */
  BinarySemWIFI_APHandle = osSemaphoreNew(1, 1, &BinarySemWIFI_AP_attributes);

  /* Create the queue(s) */
  /* creation of AudioQueue */
  AudioQueueHandle = osMessageQueueNew (5, sizeof(Type_AudioMsg), &AudioQueue_attributes);

  /* Create the thread(s) */
  /* creation of DefaultTouchGFx */
  DefaultTouchGFxHandle = osThreadNew(defaultTouchGFxTask, NULL, &DefaultTouchGFx_attributes);

  /* creation of GeneralHardware */
  GeneralHardwareHandle = osThreadNew(generalHardwareTask, NULL, &GeneralHardware_attributes);

  /* creation of AnalogDigital */
  AnalogDigitalHandle = osThreadNew(analogDigitalTask, NULL, &AnalogDigital_attributes);

  /* creation of PWM_Acceleromet */
  PWM_AccelerometHandle = osThreadNew(PWM_AccelerometerTask, NULL, &PWM_Acceleromet_attributes);

  /* creation of WIFI_AP */
  WIFI_APHandle = osThreadNew(WIFI_AP_Task, NULL, &WIFI_AP_attributes);

  /* creation of AudioPlay */
  AudioPlayHandle = osThreadNew(audioPlayTask, NULL, &AudioPlay_attributes);

}

void defaultTouchGFxTask(void *argument)
{
  /* USER CODE BEGIN defaultTouchGFxTask */
	// INIT TOUCHGFX - TOUCHGFX REQUIRES SDRAM INIT TO WORK

	SDRAM_InitSequence();
	TOUCH_RST_DISABLE();
	HAL_Delay(200);
	MX_TouchGFX_Process();
  /* Infinite loop */
  for(;;)
  {
    osDelay(1);
  }
  /* USER CODE END defaultTouchGFxTask */
}

void generalHardwareTask(void *argument)
{
  /* USER CODE BEGIN generalHardwareTask */
	main_Init();
  /* Infinite loop */
  for(;;)
  {
	main_WhileLoop();
    osDelay(1);
  }
  /* USER CODE END generalHardwareTask */
}

void analogDigitalTask(void *argument)
{
  /* USER CODE BEGIN analogDigitalTask */
	analogDigitalTask_Init();
  /* Infinite loop */
  for(;;)
  {
	analogDigitalTask_ForLoop();
    osDelay(1);
  }
  /* USER CODE END analogDigitalTask */
}

void PWM_AccelerometerTask(void *argument)
{
  /* USER CODE BEGIN PWM_AccelerometerTask */
	PWM_AccelerometerTask_Init();
  /* Infinite loop */
  for(;;)
  {
	PWM_AccelerometerTask_ForLoop();
    osDelay(1);
  }
  /* USER CODE END PWM_AccelerometerTask */
}

void WIFI_AP_Task(void *argument)
{
  /* USER CODE BEGIN WIFI_AP_Task */
	WIFI_AP_Task_Init();
  /* Infinite loop */
  for(;;)
  {
	WIFI_AP_Task_ForLoop();
    osDelay(1);
  }
  /* USER CODE END WIFI_AP_Task */
}

void audioPlayTask(void *argument)
{
  /* USER CODE BEGIN audioPlayTask */
	audioPlayTask_Init();
  /* Infinite loop */
  for(;;)
  {
	audioPlayTask_ForLoop();
    osDelay(1);
  }
  /* USER CODE END audioPlayTask */
}

/************************ (C) COPYRIGHT STMicroelectronics *****END OF FILE****/
